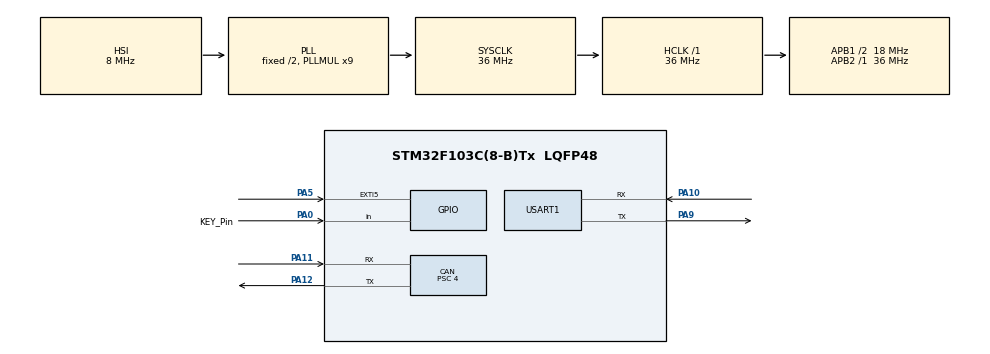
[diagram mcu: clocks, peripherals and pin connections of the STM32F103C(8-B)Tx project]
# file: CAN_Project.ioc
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CAN.ABOM=ENABLE
CAN.BS1=CAN_BS1_6TQ
CAN.BS2=CAN_BS2_2TQ
CAN.CalculateBaudRate=500000
CAN.CalculateTimeBit=2000
CAN.CalculateTimeQuantum=222.22222222222223
CAN.Mode=CAN_MODE_NORMAL
CAN.Prescaler=4
Mcu.Family=STM32F1
Mcu.Name=STM32F103C(8-B)Tx
Mcu.Package=LQFP48
NVIC.PriorityGroup=NVIC_PRIORITYGROUP_4
NVIC.USB_LP_CAN1_RX0_IRQn=true\:0\:0\:false\:false\:true\:true\:true\:true
PA0-WKUP.GPIO_Label=KEY_Pin
PA0-WKUP.GPIO_PuPd=GPIO_PULLUP
PA0-WKUP.Signal=GPIO_Input
PA10.Mode=Asynchronous
PA10.Signal=USART1_RX
PA11.Mode=CAN_Activate
PA11.Signal=CAN_RX
PA12.Mode=CAN_Activate
PA12.Signal=CAN_TX
PA13.Mode=Serial_Wire
PA13.Signal=SYS_JTMS-SWDIO
PA14.Mode=Serial_Wire
PA14.Signal=SYS_JTCK-SWCLK
PA5.Signal=GPXTI5
PA9.Mode=Asynchronous
PA9.Signal=USART1_TX
ProjectManager.HeapSize=0x200
ProjectManager.StackSize=0x400
ProjectManager.TargetToolchain=CMake
RCC.AHBFreq_Value=36000000
RCC.APB1CLKDivider=RCC_HCLK_DIV2
RCC.APB1Freq_Value=18000000
RCC.APB1TimFreq_Value=36000000
RCC.APB2Freq_Value=36000000
RCC.APB2TimFreq_Value=36000000
RCC.HCLKFreq_Value=36000000
RCC.PLLMUL=RCC_PLL_MUL9
RCC.SYSCLKFreq_VALUE=36000000
RCC.SYSCLKSource=RCC_SYSCLKSOURCE_PLLCLK
RCC.USBFreq_Value=36000000
USART1.VirtualMode=VM_ASYNC
board=custom

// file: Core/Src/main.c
/* USER CODE BEGIN Header */
/**
  ******************************************************************************
  * @file           : main.c
  * @brief          : Main program body
  ******************************************************************************
  * @attention
  *
  * Copyright (c) 2026 STMicroelectronics.
  * All rights reserved.
  *
  * This software is licensed under terms that can be found in the LICENSE file
  * in the root directory of this software component.
  * If no LICENSE file comes with this software, it is provided AS-IS.
  *
  ******************************************************************************
  */
/* USER CODE END Header */
#include "main.h"
#include "can.h"
#include "usart.h"
#include "gpio.h"

/* USER CODE BEGIN Includes */
#include "stdio.h"  // 用于printf重定向
/* USER CODE END Includes */

void SystemClock_Config(void);

/* USER CODE BEGIN 0 */

/* ========== 定义主从模式切换宏 ========== */
// 烧录主机板时，取消下面这行的注释
#define MASTER

// 烧录从机板时，取消下面这行的注释
//#define SLAVE

/* ========== 包含自定义头文件 ========== */
#include "can.h"

/* ========== 全局变量 ========== */
uint8_t last_key_state = 0;  // 用于按键边沿检测（防误触发）

/* USER CODE END 0 */

int main(void)
{

  /* MCU Configuration--------------------------------------------------------*/

  /* Reset of all peripherals, Initializes the Flash interface and the Systick. */
  HAL_Init();

  /* Configure the system clock */
  SystemClock_Config();

  /* Initialize all configured peripherals */
  MX_GPIO_Init();
  MX_CAN_Init();
  MX_USART1_UART_Init();
  /* USER CODE BEGIN 2 */

/* ========== 暂时屏蔽CAN和串口，专注LED测试 ========== */
// CAN_Init();
// printf("CAN Test Started!\r\n");
// #if defined(MASTER)
//     printf("Mode: MASTER\r\n");
// #elif defined(SLAVE)
//     printf("Mode: SLAVE\r\n");
// #endif

  /* USER CODE END 2 */

  /* Infinite loop */
  while (1)
  {

    /* USER CODE BEGIN 3 */
    /* ========== 外部LED闪烁测试（PA5） ========== */
    HAL_GPIO_WritePin(GPIOA, GPIO_PIN_5, GPIO_PIN_RESET);   // 输出低电平 → LED亮（若负极接PA5，正极接3.3V）
    for (volatile int i = 0; i < 1000000; i++);              // 粗延时
    HAL_GPIO_WritePin(GPIOA, GPIO_PIN_5, GPIO_PIN_SET);     // 输出高电平 → LED灭
    for (volatile int i = 0; i < 1000000; i++);
  }
  /* USER CODE END 3 */
}

void SystemClock_Config(void)
{
  RCC_OscInitTypeDef RCC_OscInitStruct = {0};
  RCC_ClkInitTypeDef RCC_ClkInitStruct = {0};

  /** Initializes the RCC Oscillators according to the specified parameters
  * in the RCC_OscInitTypeDef structure.
  */
  RCC_OscInitStruct.OscillatorType = RCC_OSCILLATORTYPE_HSI;
  RCC_OscInitStruct.HSIState = RCC_HSI_ON;
  RCC_OscInitStruct.HSICalibrationValue = RCC_HSICALIBRATION_DEFAULT;
  RCC_OscInitStruct.PLL.PLLState = RCC_PLL_ON;
  RCC_OscInitStruct.PLL.PLLSource = RCC_PLLSOURCE_HSI_DIV2;
  RCC_OscInitStruct.PLL.PLLMUL = RCC_PLL_MUL9;
  if (HAL_RCC_OscConfig(&RCC_OscInitStruct) != HAL_OK)
  {
    Error_Handler();
  }

  /** Initializes the CPU, AHB and APB buses clocks
  */
  RCC_ClkInitStruct.ClockType = RCC_CLOCKTYPE_HCLK|RCC_CLOCKTYPE_SYSCLK
                              |RCC_CLOCKTYPE_PCLK1|RCC_CLOCKTYPE_PCLK2;
  RCC_ClkInitStruct.SYSCLKSource = RCC_SYSCLKSOURCE_PLLCLK;
  RCC_ClkInitStruct.AHBCLKDivider = RCC_SYSCLK_DIV1;
  RCC_ClkInitStruct.APB1CLKDivider = RCC_HCLK_DIV2;
  RCC_ClkInitStruct.APB2CLKDivider = RCC_HCLK_DIV1;

  if (HAL_RCC_ClockConfig(&RCC_ClkInitStruct, FLASH_LATENCY_1) != HAL_OK)
  {
    Error_Handler();
  }
}

/* USER CODE BEGIN 4 */
int fputc(int ch, FILE *f)  // 重定向printf到串口
{
    HAL_UART_Transmit(&huart1, (uint8_t *)&ch, 1, HAL_MAX_DELAY);
    return ch;
}
/* USER CODE END 4 */

void Error_Handler(void)
{
  __disable_irq();
  while (1)
  {
  }
}
